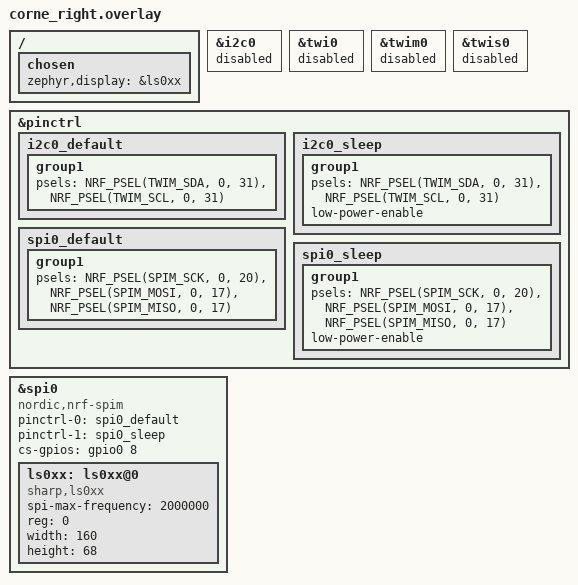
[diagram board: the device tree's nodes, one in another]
&i2c0 {
    status = "disabled";
};

&twi0 {
    status = "disabled";
};

&twim0 {
    status = "disabled";
};

&twis0 {
    status = "disabled";
};

// Override I2C pinctrl to use unused pins to avoid conflicts
&pinctrl {
    i2c0_default: i2c0_default {
        group1 {
            psels = <NRF_PSEL(TWIM_SDA, 0, 31)>,
                    <NRF_PSEL(TWIM_SCL, 0, 31)>;
        };
    };

    i2c0_sleep: i2c0_sleep {
        group1 {
            psels = <NRF_PSEL(TWIM_SDA, 0, 31)>,
                    <NRF_PSEL(TWIM_SCL, 0, 31)>;
            low-power-enable;
        };
    };
    spi0_default: spi0_default {
        group1 {
            psels = <NRF_PSEL(SPIM_SCK, 0, 20)>,
                    <NRF_PSEL(SPIM_MOSI, 0, 17)>,
                    <NRF_PSEL(SPIM_MISO, 0, 17)>;
        };
    };

    spi0_sleep: spi0_sleep {
        group1 {
            psels = <NRF_PSEL(SPIM_SCK, 0, 20)>,
                    <NRF_PSEL(SPIM_MOSI, 0, 17)>,
                    <NRF_PSEL(SPIM_MISO, 0, 17)>;
            low-power-enable;
        };
    };};

&spi0 {
    status = "okay";
    compatible = "nordic,nrf-spim";
    pinctrl-0 = <&spi0_default>;
    pinctrl-1 = <&spi0_sleep>;
    pinctrl-names = "default", "sleep";
    cs-gpios = <&gpio0 8 GPIO_ACTIVE_HIGH>;

    ls0xx: ls0xx@0 {
        compatible = "sharp,ls0xx";
        spi-max-frequency = <2000000>;
        reg = <0>;
        width = <160>;
        height = <68>;
    };
};

/ {
    chosen {
        zephyr,display = &ls0xx;
    };
};
